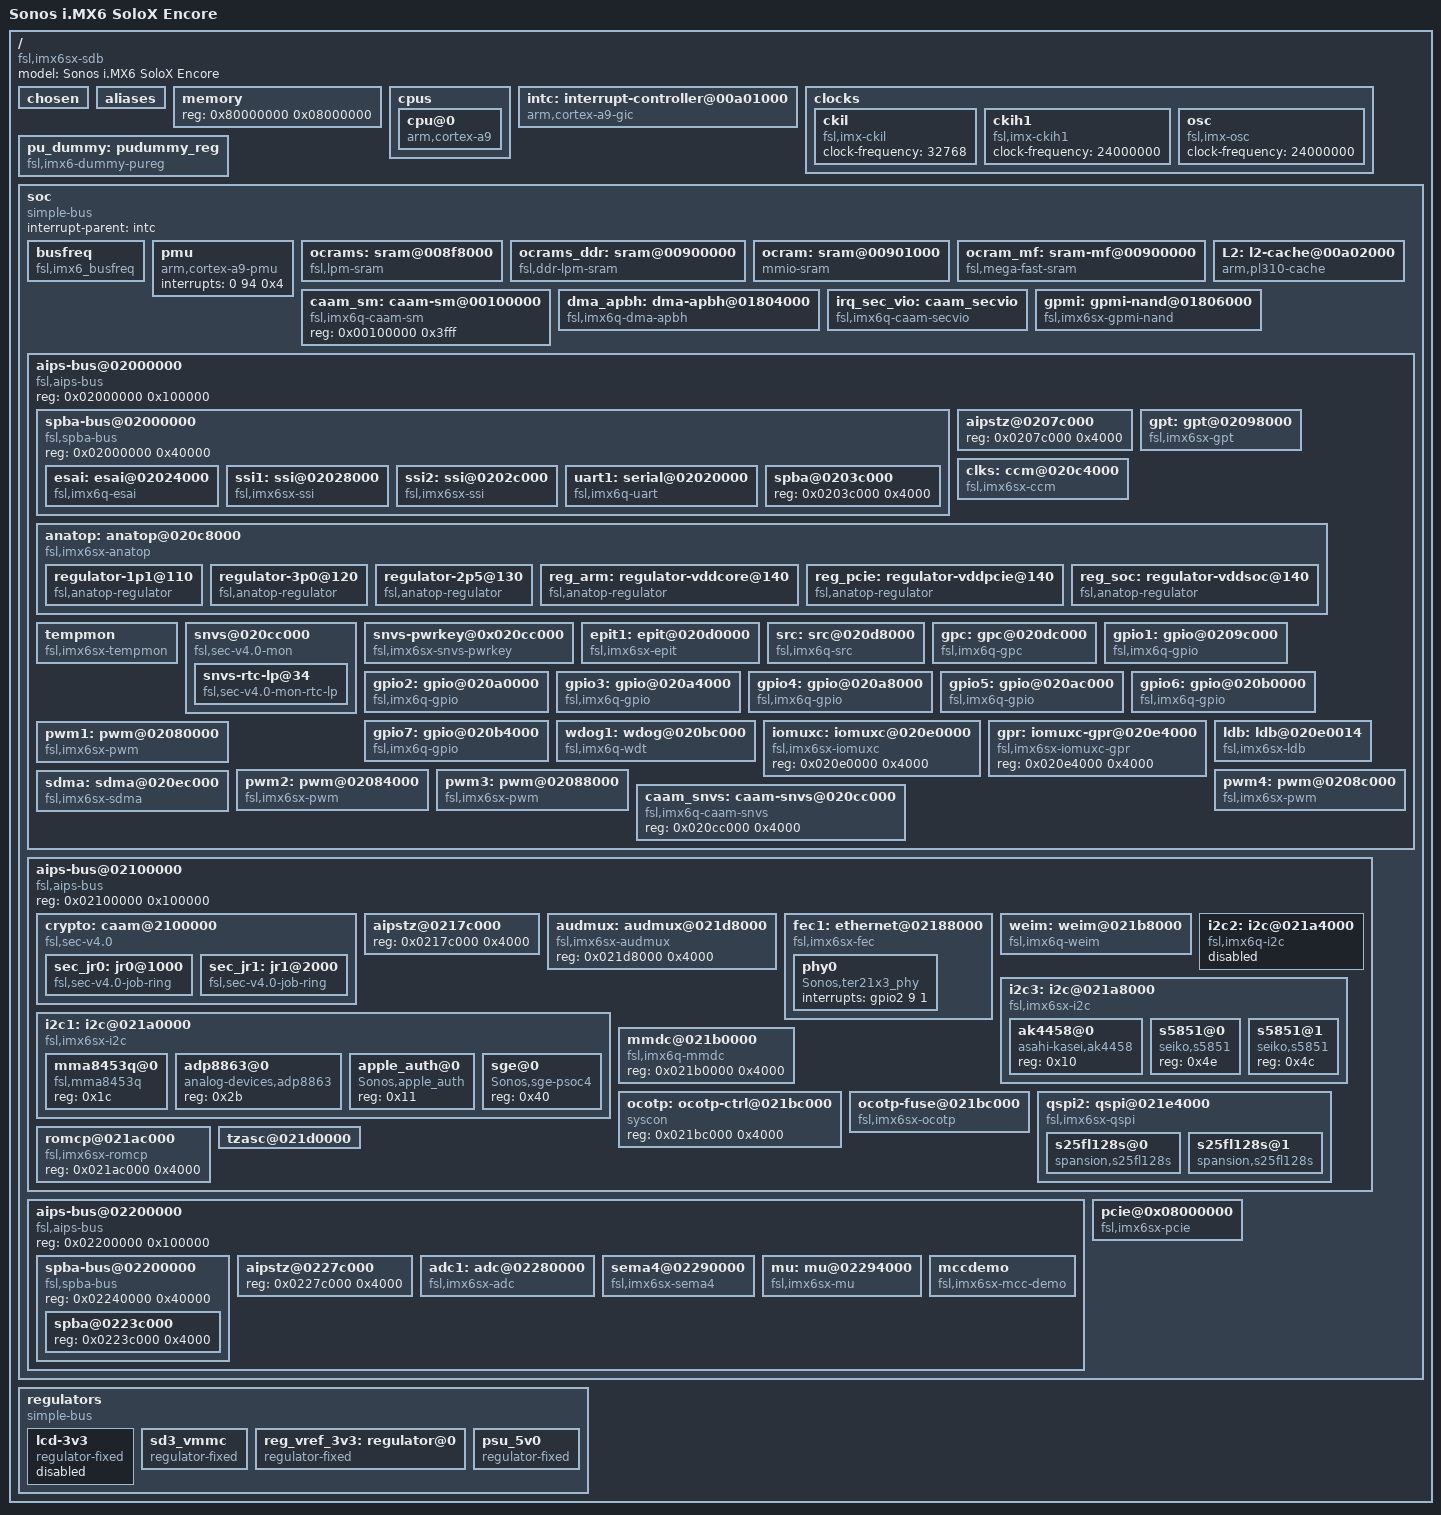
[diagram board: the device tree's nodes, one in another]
/*
 * Sonos Encore DTB
 */

/dts-v1/;

#include <dt-bindings/clock/imx6sx-clock.h>

/ {
	#address-cells = <1>;
	#size-cells = <1>;
	model = "Sonos i.MX6 SoloX Encore";
	compatible = "fsl,imx6sx-sdb", "fsl,imx6sx";

	chosen {
	};

	aliases {
		gpio0 = &gpio1;
		gpio1 = &gpio2;
		gpio2 = &gpio3;
		gpio3 = &gpio4;
		gpio4 = &gpio5;
		gpio5 = &gpio6;
		gpio6 = &gpio7;
		serial0 = &uart1;
	};

	memory {
		device_type = "memory";
		reg = <0x80000000 0x08000000>;
	};

	cpus {
		#address-cells = <1>;
		#size-cells = <0>;

		cpu@0 {
			compatible = "arm,cortex-a9";
			device_type = "cpu";
			reg = <0>;
			next-level-cache = <&L2>;
			operating-points = <
				/* kHz    uV */
				996000  1250000
				792000  1175000
				396000  1075000
			>;
			fsl,soc-operating-points = <
				/* ARM kHz      SOC uV */
				996000            1200000
				792000            1175000
				396000            1175000
			>;
			clock-latency = <61036>; /* two CLK32 periods */
			clocks = <&clks IMX6SX_CLK_ARM>, <&clks IMX6SX_CLK_PLL2_PFD2>, <&clks IMX6SX_CLK_STEP>,
				 <&clks IMX6SX_CLK_PLL1_SW>, <&clks IMX6SX_CLK_PLL1_SYS>;
			clock-names = "arm", "pll2_pfd2_396m", "step",
				      "pll1_sw", "pll1_sys";
			arm-supply = <&reg_arm>;
			soc-supply = <&reg_soc>;
		};
	};

	intc: interrupt-controller@00a01000 {
		compatible = "arm,cortex-a9-gic";
		#interrupt-cells = <3>;
		#address-cells = <1>;
		#size-cells = <1>;
		interrupt-controller;
		reg = <0x00a01000 0x1000>,
		      <0x00a00100 0x100>;
	};

	clocks {
		#address-cells = <1>;
		#size-cells = <0>;

		ckil {
			compatible = "fsl,imx-ckil", "fixed-clock";
			clock-frequency = <32768>;
		};

		ckih1 {
			compatible = "fsl,imx-ckih1", "fixed-clock";
			clock-frequency = <24000000>;
		};

		osc {
			compatible = "fsl,imx-osc", "fixed-clock";
			clock-frequency = <24000000>;
		};
	};

	pu_dummy: pudummy_reg {
		compatible = "fsl,imx6-dummy-pureg"; /* only used in ldo-bypass */
	};

	soc {
		#address-cells = <1>;
		#size-cells = <1>;
		compatible = "simple-bus";
		interrupt-parent = <&intc>;
		ranges;

		busfreq {
			compatible = "fsl,imx6_busfreq";
			clocks = <&clks IMX6SX_CLK_PLL2_BUS>, <&clks IMX6SX_CLK_PLL2_PFD2>,
				<&clks IMX6SX_CLK_PLL2_198M>, <&clks IMX6SX_CLK_ARM>,
				<&clks IMX6SX_CLK_PLL3_USB_OTG>, <&clks IMX6SX_CLK_PERIPH>,
				<&clks IMX6SX_CLK_PERIPH_PRE>, <&clks IMX6SX_CLK_PERIPH_CLK2>,
				<&clks IMX6SX_CLK_PERIPH_CLK2_SEL>, <&clks IMX6SX_CLK_OSC>,
				<&clks IMX6SX_CLK_PLL1_SYS>, <&clks IMX6SX_CLK_PERIPH2>,
				<&clks IMX6SX_CLK_AHB>, <&clks IMX6SX_CLK_OCRAM>,
				<&clks IMX6SX_CLK_PLL1_SW>, <&clks IMX6SX_CLK_PERIPH2_PRE>,
				<&clks IMX6SX_CLK_PERIPH2_CLK2_SEL>, <&clks IMX6SX_CLK_PERIPH2_CLK2>,
				<&clks IMX6SX_CLK_STEP>, <&clks IMX6SX_CLK_MMDC_P0_FAST>,
				<&clks IMX6SX_CLK_M4>;
			clock-names = "pll2_bus", "pll2_pfd2_396m", "pll2_198m", "arm", "pll3_usb_otg", "periph",
				"periph_pre", "periph_clk2", "periph_clk2_sel", "osc", "pll1_sys", "periph2", "ahb", "ocram", "pll1_sw",
				"periph2_pre", "periph2_clk2_sel", "periph2_clk2", "step", "mmdc", "m4";
			fsl,max_ddr_freq = <400000000>;
		};

		pmu {
			compatible = "arm,cortex-a9-pmu";
			interrupts = <0 94 0x4>;
		};

		ocrams: sram@008f8000 {
			compatible = "fsl,lpm-sram";
			reg = <0x008f8000 0x4000>;
			clocks = <&clks IMX6SX_CLK_OCRAM_S>;
		};

		ocrams_ddr: sram@00900000 {
			compatible = "fsl,ddr-lpm-sram";
			reg = <0x00900000 0x1000>;
			clocks = <&clks IMX6SX_CLK_OCRAM>;
		};

		ocram: sram@00901000 {
			compatible = "mmio-sram";
			reg = <0x00901000 0x1F000>;
			clocks = <&clks IMX6SX_CLK_OCRAM>;
		};

		ocram_mf: sram-mf@00900000 {
			compatible = "fsl,mega-fast-sram";
			reg = <0x00900000 0x20000>;
			clocks = <&clks IMX6SX_CLK_OCRAM>;
		};

		L2: l2-cache@00a02000 {
			compatible = "arm,pl310-cache";
			reg = <0x00a02000 0x1000>;
			interrupts = <0 92 0x4>;
			cache-unified;
			cache-level = <2>;
			arm,tag-latency = <4 2 3>;
			arm,data-latency = <4 2 3>;
		};

		caam_sm: caam-sm@00100000 {
			compatible = "fsl,imx6q-caam-sm";
			reg = <0x00100000 0x3fff>;
		};

		dma_apbh: dma-apbh@01804000 {
			compatible = "fsl,imx6q-dma-apbh", "fsl,imx28-dma-apbh";
			reg = <0x01804000 0x2000>;
			interrupts = <0 13 0x4>, <0 13 0x4>, <0 13 0x4>, <0 13 0x4>;
			interrupt-names = "gpmi0", "gpmi1", "gpmi2", "gpmi3";
			#dma-cells = <1>;
			dma-channels = <4>;
			clocks = <&clks IMX6SX_CLK_APBH_DMA>;
		};

		irq_sec_vio: caam_secvio {
			compatible = "fsl,imx6q-caam-secvio";
			interrupts = <0 20 0x04>;
			secvio_src = <0x8000001d>;
		};

		gpmi: gpmi-nand@01806000{
			compatible = "fsl,imx6sx-gpmi-nand";
			#address-cells = <1>;
			#size-cells = <1>;
			reg = <0x01806000 0x2000>, <0x01808000 0x4000>;
			reg-names = "gpmi-nand", "bch";
			interrupts = <0 15 0x4>;
			interrupt-names = "bch";
			clocks = <&clks IMX6SX_CLK_GPMI_IO>, <&clks IMX6SX_CLK_GPMI_APB>,
				 <&clks IMX6SX_CLK_GPMI_BCH>, <&clks IMX6SX_CLK_GPMI_BCH_APB>,
				 <&clks IMX6SX_CLK_PER1_BCH>;
			clock-names = "gpmi_io", "gpmi_apb", "gpmi_bch",
				      "gpmi_bch_apb", "per1_bch";
			dmas = <&dma_apbh 0>;
			dma-names = "rx-tx";
			status = "okay";
		};

		aips-bus@02000000 { /* AIPS1 */
			compatible = "fsl,aips-bus", "simple-bus";
			#address-cells = <1>;
			#size-cells = <1>;
			reg = <0x02000000 0x100000>;
			ranges;

			spba-bus@02000000 {
				compatible = "fsl,spba-bus", "simple-bus";
				#address-cells = <1>;
				#size-cells = <1>;
				reg = <0x02000000 0x40000>;
				ranges;

				esai: esai@02024000 {
					compatible = "fsl,imx6q-esai";
					reg = <0x02024000 0x4000>;
					interrupts = <0 51 0x04>;
					clocks = <&clks IMX6SX_CLK_ESAI_IPG>,
						<&clks IMX6SX_CLK_ESAI_EXTAL>,
						<&clks IMX6SX_CLK_SPBA>;
					clock-names = "core", "extal", "dma";
					dmas = <&sdma 24 21 0>, <&sdma 23 21 0>;
					dma-names = "tx", "rx";
					status = "okay";
				};

				ssi1: ssi@02028000 {
					compatible = "fsl,imx6sx-ssi", "fsl,imx21-ssi";
					reg = <0x02028000 0x4000>;
					interrupts = <0 46 0x4>;
					clocks = <&clks IMX6SX_CLK_SSI1_IPG>, <&clks IMX6SX_CLK_SSI1>;
					clock-names = "ipg", "baud";
					dev-id = <0>;
					dmas = <&sdma 37 1 0>, <&sdma 38 1 0>;
					dma-names = "rx", "tx";
					status = "okay";
				};

				ssi2: ssi@0202c000 {
					compatible = "fsl,imx6sx-ssi", "fsl,imx21-ssi";
					reg = <0x0202c000 0x4000>;
					interrupts = <0 47 0x4>;
					clocks = <&clks IMX6SX_CLK_SSI2_IPG>, <&clks IMX6SX_CLK_SSI2>;
					clock-names = "ipg", "baud";
					dev-id = <1>;
					dmas = <&sdma 41 1 0>, <&sdma 42 1 0>;
					dma-names = "rx", "tx";
					status = "okay";
				};

				uart1: serial@02020000 {
					compatible = "fsl,imx6q-uart", "fsl,imx21-uart";
					reg = <0x02020000 0x4000>;
					interrupts = <0 26 0x4>;
					clocks = <&clks IMX6SX_CLK_UART_IPG>, <&clks IMX6SX_CLK_UART_SERIAL>;
					clock-names = "ipg", "per";
					dmas = <&sdma 25 4 0>, <&sdma 26 4 0>;
					dma-names = "rx", "tx";
					status = "okay";
				};

				spba@0203c000 {
					reg = <0x0203c000 0x4000>;
				};
			};

			aipstz@0207c000 {
				reg = <0x0207c000 0x4000>;
			};

			gpt: gpt@02098000 {
				compatible = "fsl,imx6sx-gpt";
				reg = <0x02098000 0x4000>;
				interrupts = <0 55 0x4>;
				clocks = <&clks IMX6SX_CLK_GPT_BUS>, <&clks IMX6SX_CLK_GPT_SERIAL>;
				clock-names = "ipg", "per";
			};

			clks: ccm@020c4000 {
				compatible = "fsl,imx6sx-ccm";
				reg = <0x020c4000 0x4000>;
				interrupts = <0 87 0x4 0 88 0x4>;
				#clock-cells = <1>;
			};

			anatop: anatop@020c8000 {
				compatible = "fsl,imx6sx-anatop", "fsl,imx6q-anatop", "syscon", "simple-bus";
				reg = <0x020c8000 0x1000>;
				interrupts = <0 49 0x4 0 54 0x4 0 127 0x4>;

				regulator-1p1@110 {
					compatible = "fsl,anatop-regulator";
					regulator-name = "vdd1p1";
					regulator-min-microvolt = <800000>;
					regulator-max-microvolt = <1375000>;
					regulator-always-on;
					anatop-reg-offset = <0x110>;
					anatop-vol-bit-shift = <8>;
					anatop-vol-bit-width = <5>;
					anatop-min-bit-val = <4>;
					anatop-min-voltage = <800000>;
					anatop-max-voltage = <1375000>;
				};

				regulator-3p0@120 {
					compatible = "fsl,anatop-regulator";
					regulator-name = "vdd3p0";
					regulator-min-microvolt = <2800000>;
					regulator-max-microvolt = <3150000>;
					regulator-always-on;
					anatop-reg-offset = <0x120>;
					anatop-vol-bit-shift = <8>;
					anatop-vol-bit-width = <5>;
					anatop-min-bit-val = <0>;
					anatop-min-voltage = <2625000>;
					anatop-max-voltage = <3400000>;
				};

				regulator-2p5@130 {
					compatible = "fsl,anatop-regulator";
					regulator-name = "vdd2p5";
					regulator-min-microvolt = <2100000>;
					regulator-max-microvolt = <2875000>;
					regulator-always-on;
					anatop-reg-offset = <0x130>;
					anatop-vol-bit-shift = <8>;
					anatop-vol-bit-width = <5>;
					anatop-min-bit-val = <0>;
					anatop-min-voltage = <2100000>;
					anatop-max-voltage = <2875000>;
				};

				reg_arm: regulator-vddcore@140 {
					compatible = "fsl,anatop-regulator";
					regulator-name = "cpu";
					regulator-min-microvolt = <725000>;
					regulator-max-microvolt = <1450000>;
					regulator-always-on;
					anatop-reg-offset = <0x140>;
					anatop-vol-bit-shift = <0x0>;
					anatop-vol-bit-width = <0x5>;
					anatop-delay-reg-offset = <0x170>;
					anatop-delay-bit-shift = <24>;
					anatop-delay-bit-width = <2>;
					anatop-min-bit-val = <1>;
					anatop-min-voltage = <725000>;
					anatop-max-voltage = <1450000>;
				};

				reg_pcie: regulator-vddpcie@140 {
					compatible = "fsl,anatop-regulator";
					regulator-name = "vddpcie";
					regulator-min-microvolt = <725000>;
					regulator-max-microvolt = <1450000>;
					anatop-reg-offset = <0x140>;
					anatop-vol-bit-shift = <9>;
					anatop-vol-bit-width = <5>;
					anatop-delay-reg-offset = <0x170>;
					anatop-delay-bit-shift = <26>;
					anatop-delay-bit-width = <2>;
					anatop-min-bit-val = <1>;
					anatop-min-voltage = <725000>;
					anatop-max-voltage = <1450000>;
				};

				reg_soc: regulator-vddsoc@140 {
					compatible = "fsl,anatop-regulator";
					regulator-name = "vddsoc";
					regulator-min-microvolt = <725000>;
					regulator-max-microvolt = <1450000>;
					regulator-always-on;
					anatop-reg-offset = <0x140>;
					anatop-vol-bit-shift = <18>;
					anatop-vol-bit-width = <5>;
					anatop-delay-reg-offset = <0x170>;
					anatop-delay-bit-shift = <28>;
					anatop-delay-bit-width = <2>;
					anatop-min-bit-val = <1>;
					anatop-min-voltage = <725000>;
					anatop-max-voltage = <1450000>;
				};
			};

			tempmon: tempmon {	// SOC thermal sensor
				compatible = "fsl,imx6sx-tempmon", "fsl,imx6q-tempmon";
				interrupts = <0 49 0x4>;
				fsl,tempmon = <&anatop>;
				fsl,tempmon-data = <&ocotp>;
				clocks = <&clks IMX6SX_CLK_PLL3_USB_OTG>;
			};

			snvs@020cc000 {
				compatible = "fsl,sec-v4.0-mon", "simple-bus";
				#address-cells = <1>;
				#size-cells = <1>;
				ranges = <0 0x020cc000 0x4000>;

				snvs-rtc-lp@34 {
					compatible = "fsl,sec-v4.0-mon-rtc-lp";
					reg = <0x34 0x58>;
					interrupts = <0 19 0x4 0 20 0x4>;
				};
			};

			snvs-pwrkey@0x020cc000 {
				compatible = "fsl,imx6sx-snvs-pwrkey";
				reg = <0x020cc000 0x4000>;
				interrupts = <0 4 0x4>;
				fsl,keycode = <116>;
				fsl,wakeup;
			};

			epit1: epit@020d0000 {
				compatible = "fsl,imx6sx-epit";
				reg = <0x020d0000 0x4000>;
				interrupts = <0 56 0x04>;
				clocks = <&clks IMX6SX_CLK_EPIT1>,
					<&clks IMX6SX_CLK_DUMMY>,
					<&clks IMX6SX_CLK_PERCLK>,
					<&clks IMX6SX_CLK_CKIH>,
					<&clks IMX6SX_CLK_CKIL>;
				clock-names = "epit", "off", "per", "high", "low";
				dev-id = <0>;
				// This EPIT device serves as the LLA audio clock
				lla-clock;
			};

			// NOT IN USE
			/* epit2: epit@020d4000 {
				reg = <0x020d4000 0x4000>;
				interrupts = <0 57 0x04>;
				clocks = <&clks IMX6SX_CLK_EPIT2>;
				clock-names = "epit";
				dev-id = <1>;
			};*/

			src: src@020d8000 {
				compatible = "fsl,imx6q-src", "fsl,imx51-src", "syscon";
				reg = <0x020d8000 0x4000>;
				interrupts = <0 91 0x4 0 96 0x4>;
				#reset-cells = <1>;
			};

			gpc: gpc@020dc000 {
				compatible = "fsl,imx6q-gpc";
				reg = <0x020dc000 0x4000>;
				interrupts = <0 89 0x04>;
				clocks = <&clks IMX6SX_CLK_GPU>, <&clks IMX6SX_CLK_IPG>,
					<&clks IMX6SX_CLK_PXP_AXI>, <&clks IMX6SX_CLK_DISPLAY_AXI>,
					<&clks IMX6SX_CLK_LCDIF1_PIX>, <&clks IMX6SX_CLK_LCDIF_APB>,
					<&clks IMX6SX_CLK_LCDIF2_PIX>, <&clks IMX6SX_CLK_CSI>;
				clock-names = "gpu3d_core", "ipg", "pxp_axi", "disp_axi", "lcdif1_pix",
						"lcdif_axi", "lcdif2_pix", "csi_mclk";
				pu-supply = <&pu_dummy>;
				pcie-supply = <&reg_pcie>;
				fsl,mf-mix-wakeup-irq = <0x7c00000 0x3d00 0x0 0x400200>;
			};

			gpio1: gpio@0209c000 {
				compatible = "fsl,imx6q-gpio", "fsl,imx35-gpio";
				reg = <0x0209c000 0x4000>;
				interrupts = <0 66 0x4 0 67 0x4>;
				gpio-controller;
				#gpio-cells = <2>;
				interrupt-controller;
				#interrupt-cells = <2>;
			};

			gpio2: gpio2: gpio@020a0000 {
				compatible = "fsl,imx6q-gpio", "fsl,imx35-gpio";
				reg = <0x020a0000 0x4000>;
				interrupts = <0 68 0x4 0 69 0x4>;
				gpio-controller;
				#gpio-cells = <2>;
				interrupt-controller;
				#interrupt-cells = <2>;
			};

			gpio3: gpio@020a4000 {
				compatible = "fsl,imx6q-gpio", "fsl,imx35-gpio";
				reg = <0x020a4000 0x4000>;
				interrupts = <0 70 0x4 0 71 0x4>;
				gpio-controller;
				#gpio-cells = <2>;
				interrupt-controller;
				#interrupt-cells = <2>;
			};

			gpio4: gpio@020a8000 {
				compatible = "fsl,imx6q-gpio", "fsl,imx35-gpio";
				reg = <0x020a8000 0x4000>;
				interrupts = <0 72 0x4 0 73 0x4>;
				gpio-controller;
				#gpio-cells = <2>;
				interrupt-controller;
				#interrupt-cells = <2>;
			};

			gpio5: gpio@020ac000 {
				compatible = "fsl,imx6q-gpio", "fsl,imx35-gpio";
				reg = <0x020ac000 0x4000>;
				interrupts = <0 74 0x4 0 75 0x4>;
				gpio-controller;
				#gpio-cells = <2>;
				interrupt-controller;
				#interrupt-cells = <2>;
			};

			gpio6: gpio@020b0000 {
				compatible = "fsl,imx6q-gpio", "fsl,imx35-gpio";
				reg = <0x020b0000 0x4000>;
				interrupts = <0 76 0x4 0 77 0x4>;
				gpio-controller;
				#gpio-cells = <2>;
				interrupt-controller;
				#interrupt-cells = <2>;
			};

			gpio7: gpio@020b4000 {
				compatible = "fsl,imx6q-gpio", "fsl,imx35-gpio";
				reg = <0x020b4000 0x4000>;
				interrupts = <0 78 0x4 0 79 0x4>;
				gpio-controller;
				#gpio-cells = <2>;
				interrupt-controller;
				#interrupt-cells = <2>;
			};

			wdog1: wdog@020bc000 {
				compatible = "fsl,imx6q-wdt", "fsl,imx21-wdt";
				reg = <0x020bc000 0x4000>;
				interrupts = <0 80 0x4>;
				clocks = <&clks IMX6SX_CLK_DUMMY>;
			};

			iomuxc: iomuxc@020e0000 {
				compatible = "fsl,imx6sx-iomuxc";
				reg = <0x020e0000 0x4000>;
			};

			gpr: iomuxc-gpr@020e4000 {
				compatible = "fsl,imx6sx-iomuxc-gpr", "syscon";
				reg = <0x020e4000 0x4000>;
			};

			ldb: ldb@020e0014 {
				#address-cells = <1>;
				#size-cells = <0>;
				compatible = "fsl,imx6sx-ldb", "fsl,imx53-ldb";
				gpr = <&gpr>;
				status = "okay";
				clocks = <&clks IMX6SX_CLK_LDB_DI0>,
					<&clks IMX6SX_CLK_LCDIF1_SEL>,
					<&clks IMX6SX_CLK_LCDIF2_SEL>,
					<&clks IMX6SX_CLK_LDB_DI0_DIV_3_5>,
					<&clks IMX6SX_CLK_LDB_DI0_DIV_7>,
					<&clks IMX6SX_CLK_LDB_DI0_DIV_SEL>;
				clock-names = "ldb_di0",
						"di0_sel",
						"di1_sel",
						"ldb_di0_div_3_5",
						"ldb_di0_div_7",
						"ldb_di0_div_sel";
			};

			pwm1: pwm@02080000 {
				#pwm-cells = <2>;
				compatible = "fsl,imx6sx-pwm", "fsl,imx27-pwm";
				reg = <0x02080000 0x4000>;
				interrupts = <0 83 0x4>;
				clocks = <&clks IMX6SX_CLK_PWM1>, <&clks IMX6SX_CLK_PWM1>;
				clock-names = "ipg", "per";
			};

			pwm2: pwm@02084000 {	// control WiFi 5Volt rail
				#pwm-cells = <2>;
				compatible = "fsl,imx6sx-pwm", "fsl,imx27-pwm";
				reg = <0x02084000 0x4000>;
				interrupts = <0 84 0x4>;
				clocks = <&clks IMX6SX_CLK_PWM2>, <&clks IMX6SX_CLK_PWM2>;
				clock-names = "ipg", "per";
				status = "okay";
			};

			pwm3: pwm@02088000 {
				#pwm-cells = <2>;
				compatible = "fsl,imx6sx-pwm", "fsl,imx27-pwm";
				reg = <0x02088000 0x4000>;
				interrupts = <0 85 0x4>;
				clocks = <&clks IMX6SX_CLK_PWM3>, <&clks IMX6SX_CLK_PWM3>;
				clock-names = "ipg", "per";
				status = "okay";
			};

			pwm4: pwm@0208c000 {
				#pwm-cells = <2>;
				compatible = "fsl,imx6sx-pwm", "fsl,imx27-pwm";
				reg = <0x0208c000 0x4000>;
				interrupts = <0 86 0x4>;
				clocks = <&clks IMX6SX_CLK_PWM4>, <&clks IMX6SX_CLK_PWM4>;
				clock-names = "ipg", "per";
				status = "okay";
			};

			sdma: sdma@020ec000 {
				compatible = "fsl,imx6sx-sdma";
				reg = <0x020ec000 0x4000>;
				interrupts = <0 2 0x4>;
				clocks = <&clks IMX6SX_CLK_SDMA>, <&clks IMX6SX_CLK_SDMA>;
				clock-names = "ipg", "ahb";
				#dma-cells = <3>;
				gpr = <&gpr>;
				fsl,sdma-ram-script-name = "imx/sdma/sdma-imx6q.bin";
			};

			caam_snvs: caam-snvs@020cc000 {
				compatible = "fsl,imx6q-caam-snvs";
				reg = <0x020cc000 0x4000>;
			};

		};

		aips-bus@02100000 { /* AIPS2 */
			compatible = "fsl,aips-bus", "simple-bus";
			#address-cells = <1>;
			#size-cells = <1>;
			reg = <0x02100000 0x100000>;
			ranges;

			crypto: caam@2100000 {
				compatible = "fsl,sec-v4.0";
				#address-cells = <1>;
				#size-cells = <1>;
				reg = <0x2100000 0x40000>;
				ranges = <0 0x2100000 0x40000>;
				interrupt-parent = <&intc>; /* interrupts = <0 92 0x4>; */
				clocks = <&clks 134>, <&clks 135>, <&clks 136> ,<&clks 213>;
				clock-names = "caam_mem", "caam_aclk", "caam_ipg", "caam_emi_slow";

				sec_jr0: jr0@1000 {
					compatible = "fsl,sec-v4.0-job-ring";
					reg = <0x1000 0x1000>;
					interrupt-parent = <&intc>;
					interrupts = <0 105 0x4>;
				};

				sec_jr1: jr1@2000 {
					compatible = "fsl,sec-v4.0-job-ring";
					reg = <0x2000 0x1000>;
					interrupt-parent = <&intc>;
					interrupts = <0 106 0x4>;
				};
			};

			aipstz@0217c000 { /* AIPSTZ2 */
				reg = <0x0217c000 0x4000>;
			};

			audmux: audmux@021d8000 {
				compatible = "fsl,imx6sx-audmux", "fsl,imx31-audmux";
				reg = <0x021d8000 0x4000>;
				status = "okay";
			};

			fec1: ethernet@02188000 {
				compatible = "fsl,imx6sx-fec";
				reg = <0x02188000 0x4000>;
				interrupts = <0 118 0x04 0 119 0x04>;
				clocks = <&clks IMX6SX_CLK_ENET>, <&clks IMX6SX_CLK_ENET_AHB>,
					<&clks IMX6SX_CLK_ENET_PTP>, <&clks IMX6SX_CLK_ENET_REF>,
					<&clks IMX6SX_CLK_ENET_PTP>;
				clock-names = "ipg", "ahb", "ptp", "enet_clk_ref", "enet_out";
				status = "okay";
				phy-mode = "mii";
				fsl,num_tx_queues = <0x3>;
				fsl,num_rx_queues = <0x3>;

				phy0 {
					compatible = "Sonos,ter21x3_phy";
					interrupts = <&gpio2 9 1>;
				};
			};

			weim: weim@021b8000 {
				compatible = "fsl,imx6q-weim";
				reg = <0x021b8000 0x4000>;
				interrupts = <0 14 0x4>;
				clocks = <&clks IMX6SX_CLK_EIM_SLOW>;
			};

			i2c1: i2c@021a0000 {
				#address-cells = <1>;
				#size-cells = <0>;
				compatible = "fsl,imx6sx-i2c", "fsl,imx21-i2c";
				reg = <0x021a0000 0x4000>;
				interrupts = <0 36 0x4>;
				clocks = <&clks IMX6SX_CLK_I2C1>;
				status = "okay";
				clock-frequency = <0x186a0>;

				mma8453q@0 {	// Accelerometer
					compatible = "fsl,mma8453q";
					reg = <0x1c>;
				};
				adp8863@0 {	// LED controller
					compatible = "analog-devices,adp8863";
					reg = <0x2b>;
				};

				apple_auth@0 { // Apple Authentication Chip
					compatible = "Sonos,apple_auth";
					reg = <0x11>;
				};

				sge@0 {  // Sigdetail Gesture Engine
					compatible = "Sonos,sge-psoc4";
					reg = <0x40>;
				};
			};

			i2c2: i2c@021a4000 {
				#address-cells = <1>;
				#size-cells = <0>;
				compatible = "fsl,imx6q-i2c", "fsl,imx21-i2c";
				reg = <0x021a4000 0x4000>;
				interrupts = <0 37 0x4>;
				clocks = <0x2 IMX6SX_CLK_I2C2>;
				status = "disable";
				clock-frequency = <0x186a0>;
			};

			i2c3: i2c@021a8000 {
				#address-cells = <1>;
				#size-cells = <0>;
				compatible = "fsl,imx6sx-i2c", "fsl,imx21-i2c";
				reg = <0x021a8000 0x4000>;
				interrupts = <0 38 0x4>;
				clocks = <&clks IMX6SX_CLK_I2C3>;
				status = "okay";
				clock-frequency = <0x186a0>;

				ak4458@0 {
					compatible = "asahi-kasei,ak4458";
					reg = <0x10>;
				};

				s5851@0 {	// CPU thermal sensor
					compatible = "seiko,s5851";
					reg = <0x4e>;
					device_type = "CPU";
				};

				s5851@1 {	// Amp thermal sensor
					compatible = "seiko,s5851";
					reg = <0x4c>;
					device_type = "AMP";
				};
			};

			mmdc@021b0000 {
				compatible = "fsl,imx6q-mmdc";
				reg = <0x021b0000 0x4000>;
			};

			ocotp: ocotp-ctrl@021bc000 {
				compatible = "syscon";
				reg = <0x021bc000 0x4000>;
			};

			ocotp-fuse@021bc000 {
				compatible = "fsl,imx6sx-ocotp", "fsl,imx6q-ocotp";
				reg = <0x021bc000 0x4000>;
				clocks = <&clks IMX6SX_CLK_OCOTP>;
			};

			qspi2: qspi@021e4000 {
				#address-cells = <1>;
				#size-cells = <0>;
				compatible = "fsl,imx6sx-qspi";
				reg = <0x021e4000 0x4000>, <0x70000000 0x10000000>;
				reg-names = "QuadSPI", "QuadSPI-memory";
				interrupts = <0 109 0x4>;
				clocks = <&clks IMX6SX_CLK_QSPI2>,
					<&clks IMX6SX_CLK_QSPI2>;
				clock-names = "qspi_en", "qspi";
				status = "okay";
				pinctrl-names = "default";
				pinctrl-0 = <0x34>;

				s25fl128s@0 {
					#address-cells = <0x1>;
					#size-cells = <0x1>;
					compatible = "spansion,s25fl128s";
					spi-max-frequency = <0x3ef1480>;
					reg = <0x0>;
				};

				s25fl128s@1 {
					#address-cells = <0x1>;
					#size-cells = <0x1>;
					compatible = "spansion,s25fl128s";
					spi-max-frequency = <0x3ef1480>;
					reg = <0x1>;
				};
			};

			romcp@021ac000 {
				compatible = "fsl,imx6sx-romcp", "syscon";
				reg = <0x021ac000 0x4000>;
			};

			tzasc@021d0000 {
				reg = <0x021d0000 0x4000>;
				interrupts = <0 108 0x4>;
			};

		};

		aips-bus@02200000 { /* AIPS3 */
			compatible = "fsl,aips-bus", "simple-bus";
			#address-cells = <1>;
			#size-cells = <1>;
			reg = <0x02200000 0x100000>;
			ranges;

			spba-bus@02200000 {
				compatible = "fsl,spba-bus", "simple-bus";
				#address-cells = <1>;
				#size-cells = <1>;
				reg = <0x02240000 0x40000>;
				ranges;

				spba@0223c000 {
					reg = <0x0223c000 0x4000>;
				};
			};

			aipstz@0227c000 { /* AIPSTZ3 */
				reg = <0x0227c000 0x4000>;
			};

			adc1: adc@02280000 {
				compatible = "fsl,imx6sx-adc", "fsl,vf610-adc";
				reg = <0x02280000 0x4000>;
				interrupts = <0 100 0x4>;
				clocks = <&clks IMX6SX_CLK_IPG>;
				clock-names = "adc";
				num-channels = <2>;
				status = "okay";
				vref-supply = <&reg_vref_3v3>;
			};

			sema4@02290000 {
				compatible = "fsl,imx6sx-sema4";
				reg = <0x02290000 0x4000>;
				interrupts = <0 116 0x4>;
				status = "okay";
			};

			mu: mu@02294000 {
				compatible = "fsl,imx6sx-mu", "syscon";
				reg = <0x02294000 0x4000>;
				interrupts = <0 99 0x4>;
			};

			mccdemo {
				compatible = "fsl,imx6sx-mcc-demo";
				status = "okay";
			};
		};

		pcie@0x08000000 {
			compatible = "fsl,imx6sx-pcie", "snps,dw-pcie";
			reg = <0x08ffc000 0x4000>;
			#address-cells = <3>;
			#size-cells = <2>;
			device_type = "pci";
			ranges = <0x00000800 0 0x08f00000 0x08f00000 0 0x00080000 /* configuration space */
				  0x81000000 0 0          0x08f80000 0 0x00010000 /* downstream I/O */
				  0x82000000 0 0x08000000 0x08000000 0 0x00f00000>; /* non-prefetchable memory */
			num-lanes = <1>;
			interrupts = <0 123 0x4>;
			clocks = <&clks IMX6SX_CLK_PCIE_REF_125M>, <&clks IMX6SX_CLK_PCIE_AXI>,
				<&clks IMX6SX_CLK_LVDS1_OUT>, <&clks IMX6SX_CLK_DISPLAY_AXI>;
			clock-names = "pcie_ref_125m", "pcie_axi", "lvds_gate", "display_axi";
			pcie-supply = <&reg_pcie>;
			status = "okay";
			reset-gpio = <&gpio2 0x12 0x0>;
		};
	};

	regulators {
		compatible = "simple-bus";

		lcd-3v3 {
			compatible = "regulator-fixed";
			regulator-name = "lcd-3v3";
			gpio = <0x1f 0x1b 0x0>;
			enable-active-high;
			status = "disabled";
		};

		sd3_vmmc {
			compatible = "regulator-fixed";
			regulator-name = "VCC_SD3";
			regulator-min-microvolt = <0x2dc6c0>;
			regulator-max-microvolt = <0x2dc6c0>;
			gpio = <0x18 0xb 0x0>;
			enable-active-high;
		};

		reg_vref_3v3: regulator@0 {
			compatible = "regulator-fixed";
			regulator-name = "vref-3v3";
			regulator-min-microvolt = <0x325aa0>;
			regulator-max-microvolt = <0x325aa0>;
		};

		psu_5v0 {
			compatible = "regulator-fixed";
			regulator-name = "PSU-5V0";
			regulator-min-microvolt = <0x4c4b40>;
			regulator-max-microvolt = <0x4c4b40>;
			regulator-boot-on;
		};
	};
};
